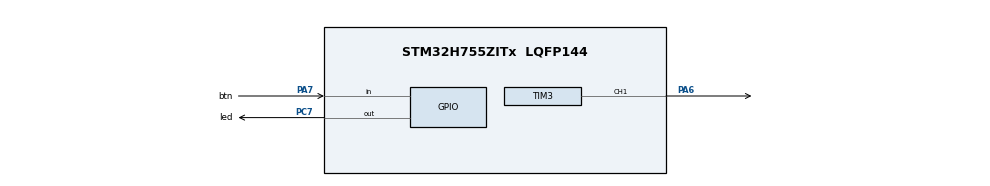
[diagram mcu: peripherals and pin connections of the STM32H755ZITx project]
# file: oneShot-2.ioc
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CortexM4.IPs=FATFS_M4\:I,FREERTOS_M4\:I,IWDG2\:I,RCC,WWDG2\:I,DMA,BDMA,MDMA,NVIC2\:I,ETH,USART3,DEBUG,USB_DEVICE_M4\:I,USB_HOST_M4\:I,PDM2PCM_M4\:I,PWR,RESMGR_UTILITY,SYS_M4\:I,CORTEX_M4\:I,OPENAMP_M4\:I,VREFBUF,GPIO
CortexM7.IPs=FATFS_M7\:I,FREERTOS_M7\:I,IWDG1\:I,RCC\:I,WWDG1\:I,DMA\:I,BDMA\:I,MDMA\:I,NVIC1\:I,ETH\:I,USART3\:I,USB_OTG_FS\:I,SYS\:I,CORTEX_M7\:I,DEBUG\:I,USB_DEVICE_M7\:I,USB_HOST_M7\:I,PDM2PCM_M7\:I,PWR\:I,RESMGR_UTILITY\:I,OPENAMP_M7\:I,VREFBUF\:I,GPIO\:I,TIM3\:I
CortexM7.Pins=PA7,PC7
Mcu.Family=STM32H7
Mcu.Name=STM32H755ZITx
Mcu.Package=LQFP144
NVIC1.PriorityGroup=NVIC_PRIORITYGROUP_4
NVIC1.TIM3_IRQn=true\:0\:0\:false\:false\:true\:true\:true\:true
NVIC2.PriorityGroup=NVIC_PRIORITYGROUP_4
PA6.PinAttribute=CortexM7
PA6.Signal=S_TIM3_CH1
PA7.GPIO_Label=btn
PA7.PinAttribute=CortexM7
PA7.Signal=GPIO_Input
PC14-OSC32_IN\ (OSC32_IN).Mode=LSE-External-Oscillator
PC14-OSC32_IN\ (OSC32_IN).PinAttribute=Free
PC14-OSC32_IN\ (OSC32_IN).Signal=RCC_OSC32_IN
PC15-OSC32_OUT\ (OSC32_OUT).Mode=LSE-External-Oscillator
PC15-OSC32_OUT\ (OSC32_OUT).PinAttribute=Free
PC15-OSC32_OUT\ (OSC32_OUT).Signal=RCC_OSC32_OUT
PC7.GPIO_Label=led
PC7.PinAttribute=CortexM7
PC7.Signal=GPIO_Output
PH0-OSC_IN\ (PH0).Mode=HSE-External-Clock-Source
PH0-OSC_IN\ (PH0).PinAttribute=Free
PH0-OSC_IN\ (PH0).Signal=RCC_OSC_IN
ProjectManager.HeapSize=M4-0x200,M7-0x200
ProjectManager.StackSize=M4-0x400,M7-0x400
ProjectManager.TargetToolchain=STM32CubeIDE
RCC.ADCFreq_Value=129000000
RCC.APB1Freq_Value=64000000
RCC.APB2Freq_Value=64000000
RCC.APB3Freq_Value=64000000
RCC.APB4Freq_Value=64000000
RCC.CortexFreq_Value=64000000
RCC.DIVM1=4
RCC.DIVN1=60
RCC.DIVP1=4
RCC.DIVQ1=4
RCC.HCLKFreq_Value=64000000
RCC.HSE_VALUE=8000000
RCC.PLL2FRACN=0
RCC.PLL3FRACN=0
RCC.PLLFRACN=0
RCC.PWR_Regulator_Voltage_Scale=PWR_REGULATOR_VOLTAGE_SCALE2
RCC.SYSCLKFreq_VALUE=64000000
RCC.SupplySource=PWR_DIRECT_SMPS_SUPPLY
RCC.USBFreq_Value=240000000
SH.S_TIM3_CH1.0=TIM3_CH1,Output Compare1 CH1
TIM3.Channel-Output\ Compare1\ CH1=TIM_CHANNEL_1
TIM3.OC1Preload=DISABLE
TIM3.OCMode_1=TIM_OCMODE_TIMING
TIM3.Period=65535
TIM3.Prescaler=63999
TIM3.Pulse-Output\ Compare1\ CH1=0
TIM3.TIM_MasterOutputTrigger=TIM_TRGO_UPDATE
VP_SYS_M4_VS_Systick.Mode=SysTick
VP_TIM3_VS_ClockSourceINT.Mode=Internal
board=NUCLEO-H755ZI-Q

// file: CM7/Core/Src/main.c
/* USER CODE BEGIN Header */
/**
  ******************************************************************************
  * @file           : main.c
  * @brief          : Main program body
  ******************************************************************************
  * @attention
  *
  * Copyright (c) 2026 STMicroelectronics.
  * All rights reserved.
  *
  * This software is licensed under terms that can be found in the LICENSE file
  * in the root directory of this software component.
  * If no LICENSE file comes with this software, it is provided AS-IS.
  *
  ******************************************************************************
  */
/* USER CODE END Header */
#include "main.h"

/* USER CODE BEGIN PD */

#ifndef HSEM_ID_0
#define HSEM_ID_0 (0U) /* HW semaphore 0*/
#endif

/* USER CODE END PD */

TIM_HandleTypeDef htim3;

void SystemClock_Config(void);
static void MX_GPIO_Init(void);
static void MX_TIM3_Init(void);

/* USER CODE BEGIN 0 */
volatile uint8_t g_done = 0;
volatile uint8_t g_state = 0;

volatile const uint16_t DELAT_MS = 1000;

void HAL_TIM_OC_DelayElapsedCallback(TIM_HandleTypeDef *htim)
{
	if (htim->Instance != TIM3) return;

	if (htim->Channel != HAL_TIM_ACTIVE_CHANNEL_1) return;

	if(g_state == 1)
	{
		HAL_GPIO_WritePin(led_GPIO_Port, led_Pin, GPIO_PIN_SET);

		uint16_t ccr = __HAL_TIM_GET_COMPARE(htim, TIM_CHANNEL_1);
		__HAL_TIM_SET_COMPARE(htim, TIM_CHANNEL_1,(uint16_t)(ccr + DELAT_MS));

		g_state = 2;
	}
	else if (g_state == 2)
	{

		HAL_GPIO_WritePin(led_GPIO_Port, led_Pin, GPIO_PIN_RESET);

		HAL_TIM_OC_Stop_IT(htim, TIM_CHANNEL_1);
		g_done = 1;
		g_state = 0;
	}
}
/* USER CODE END 0 */

int main(void)
{
/* USER CODE BEGIN Boot_Mode_Sequence_0 */
  int32_t timeout;
/* USER CODE END Boot_Mode_Sequence_0 */

/* USER CODE BEGIN Boot_Mode_Sequence_1 */
  /* Wait until CPU2 boots and enters in stop mode or timeout*/
  timeout = 0xFFFF;
  while((__HAL_RCC_GET_FLAG(RCC_FLAG_D2CKRDY) != RESET) && (timeout-- > 0));
  if ( timeout < 0 )
  {
  Error_Handler();
  }
/* USER CODE END Boot_Mode_Sequence_1 */
  /* MCU Configuration--------------------------------------------------------*/

  /* Reset of all peripherals, Initializes the Flash interface and the Systick. */
  HAL_Init();

  /* Configure the system clock */
  SystemClock_Config();
/* USER CODE BEGIN Boot_Mode_Sequence_2 */
/* When system initialization is finished, Cortex-M7 will release Cortex-M4 by means of
HSEM notification */
/*HW semaphore Clock enable*/
__HAL_RCC_HSEM_CLK_ENABLE();
/*Take HSEM */
HAL_HSEM_FastTake(HSEM_ID_0);
/*Release HSEM in order to notify the CPU2(CM4)*/
HAL_HSEM_Release(HSEM_ID_0,0);
/* wait until CPU2 wakes up from stop mode */
timeout = 0xFFFF;
while((__HAL_RCC_GET_FLAG(RCC_FLAG_D2CKRDY) == RESET) && (timeout-- > 0));
if ( timeout < 0 )
{
Error_Handler();
}
/* USER CODE END Boot_Mode_Sequence_2 */

  /* Initialize all configured peripherals */
  MX_GPIO_Init();
  MX_TIM3_Init();

  /* Infinite loop */
  while (1)
  {

    /* USER CODE BEGIN 3 */
	  if((HAL_GPIO_ReadPin(btn_GPIO_Port, btn_Pin) == GPIO_PIN_SET ) &&
			  !g_done && g_state == 0)
	  {
		  g_state = 1; // first push

		  // LED RESET
		  HAL_GPIO_WritePin(led_GPIO_Port, led_Pin, GPIO_PIN_RESET);

		  // time reference reset
		  __HAL_TIM_SET_COUNTER(&htim3, 0);

		  // Compare before 1 sec
		  __HAL_TIM_SET_COMPARE(&htim3, TIM_CHANNEL_1, DELAT_MS);

		  // CCR1 flag clear
		  __HAL_TIM_CLEAR_FLAG(&htim3,TIM_FLAG_CC1);

		  HAL_TIM_OC_Start_IT(&htim3, TIM_CHANNEL_1);
	  }

  }
  /* USER CODE END 3 */
}

void SystemClock_Config(void)
{
  RCC_OscInitTypeDef RCC_OscInitStruct = {0};
  RCC_ClkInitTypeDef RCC_ClkInitStruct = {0};

  /** Supply configuration update enable
  */
  HAL_PWREx_ConfigSupply(PWR_DIRECT_SMPS_SUPPLY);

  /** Configure the main internal regulator output voltage
  */
  __HAL_PWR_VOLTAGESCALING_CONFIG(PWR_REGULATOR_VOLTAGE_SCALE2);

  while(!__HAL_PWR_GET_FLAG(PWR_FLAG_VOSRDY)) {}

  /** Initializes the RCC Oscillators according to the specified parameters
  * in the RCC_OscInitTypeDef structure.
  */
  RCC_OscInitStruct.OscillatorType = RCC_OSCILLATORTYPE_HSI;
  RCC_OscInitStruct.HSIState = RCC_HSI_DIV1;
  RCC_OscInitStruct.HSICalibrationValue = RCC_HSICALIBRATION_DEFAULT;
  RCC_OscInitStruct.PLL.PLLState = RCC_PLL_NONE;
  if (HAL_RCC_OscConfig(&RCC_OscInitStruct) != HAL_OK)
  {
    Error_Handler();
  }

  /** Initializes the CPU, AHB and APB buses clocks
  */
  RCC_ClkInitStruct.ClockType = RCC_CLOCKTYPE_HCLK|RCC_CLOCKTYPE_SYSCLK
                              |RCC_CLOCKTYPE_PCLK1|RCC_CLOCKTYPE_PCLK2
                              |RCC_CLOCKTYPE_D3PCLK1|RCC_CLOCKTYPE_D1PCLK1;
  RCC_ClkInitStruct.SYSCLKSource = RCC_SYSCLKSOURCE_HSI;
  RCC_ClkInitStruct.SYSCLKDivider = RCC_SYSCLK_DIV1;
  RCC_ClkInitStruct.AHBCLKDivider = RCC_HCLK_DIV1;
  RCC_ClkInitStruct.APB3CLKDivider = RCC_APB3_DIV1;
  RCC_ClkInitStruct.APB1CLKDivider = RCC_APB1_DIV1;
  RCC_ClkInitStruct.APB2CLKDivider = RCC_APB2_DIV1;
  RCC_ClkInitStruct.APB4CLKDivider = RCC_APB4_DIV1;

  if (HAL_RCC_ClockConfig(&RCC_ClkInitStruct, FLASH_LATENCY_1) != HAL_OK)
  {
    Error_Handler();
  }
}

static void MX_TIM3_Init(void)
{

  TIM_ClockConfigTypeDef sClockSourceConfig = {0};
  TIM_MasterConfigTypeDef sMasterConfig = {0};
  TIM_OC_InitTypeDef sConfigOC = {0};

  htim3.Instance = TIM3;
  htim3.Init.Prescaler = 63999;
  htim3.Init.CounterMode = TIM_COUNTERMODE_UP;
  htim3.Init.Period = 65535;
  htim3.Init.ClockDivision = TIM_CLOCKDIVISION_DIV1;
  htim3.Init.AutoReloadPreload = TIM_AUTORELOAD_PRELOAD_DISABLE;
  if (HAL_TIM_Base_Init(&htim3) != HAL_OK)
  {
    Error_Handler();
  }
  sClockSourceConfig.ClockSource = TIM_CLOCKSOURCE_INTERNAL;
  if (HAL_TIM_ConfigClockSource(&htim3, &sClockSourceConfig) != HAL_OK)
  {
    Error_Handler();
  }
  if (HAL_TIM_OC_Init(&htim3) != HAL_OK)
  {
    Error_Handler();
  }
  sMasterConfig.MasterOutputTrigger = TIM_TRGO_UPDATE;
  sMasterConfig.MasterSlaveMode = TIM_MASTERSLAVEMODE_DISABLE;
  if (HAL_TIMEx_MasterConfigSynchronization(&htim3, &sMasterConfig) != HAL_OK)
  {
    Error_Handler();
  }
  sConfigOC.OCMode = TIM_OCMODE_TIMING;
  sConfigOC.Pulse = 0;
  sConfigOC.OCPolarity = TIM_OCPOLARITY_HIGH;
  sConfigOC.OCFastMode = TIM_OCFAST_DISABLE;
  if (HAL_TIM_OC_ConfigChannel(&htim3, &sConfigOC, TIM_CHANNEL_1) != HAL_OK)
  {
    Error_Handler();
  }
  HAL_TIM_MspPostInit(&htim3);

}

static void MX_GPIO_Init(void)
{
  GPIO_InitTypeDef GPIO_InitStruct = {0};

  /* GPIO Ports Clock Enable */
  __HAL_RCC_GPIOA_CLK_ENABLE();
  __HAL_RCC_GPIOC_CLK_ENABLE();

  /*Configure GPIO pin Output Level */
  HAL_GPIO_WritePin(led_GPIO_Port, led_Pin, GPIO_PIN_RESET);

  /*Configure GPIO pin : btn_Pin */
  GPIO_InitStruct.Pin = btn_Pin;
  GPIO_InitStruct.Mode = GPIO_MODE_INPUT;
  GPIO_InitStruct.Pull = GPIO_NOPULL;
  HAL_GPIO_Init(btn_GPIO_Port, &GPIO_InitStruct);

  /*Configure GPIO pin : led_Pin */
  GPIO_InitStruct.Pin = led_Pin;
  GPIO_InitStruct.Mode = GPIO_MODE_OUTPUT_PP;
  GPIO_InitStruct.Pull = GPIO_NOPULL;
  GPIO_InitStruct.Speed = GPIO_SPEED_FREQ_LOW;
  HAL_GPIO_Init(led_GPIO_Port, &GPIO_InitStruct);

}

void Error_Handler(void)
{
  __disable_irq();
  while (1)
  {
  }
}
